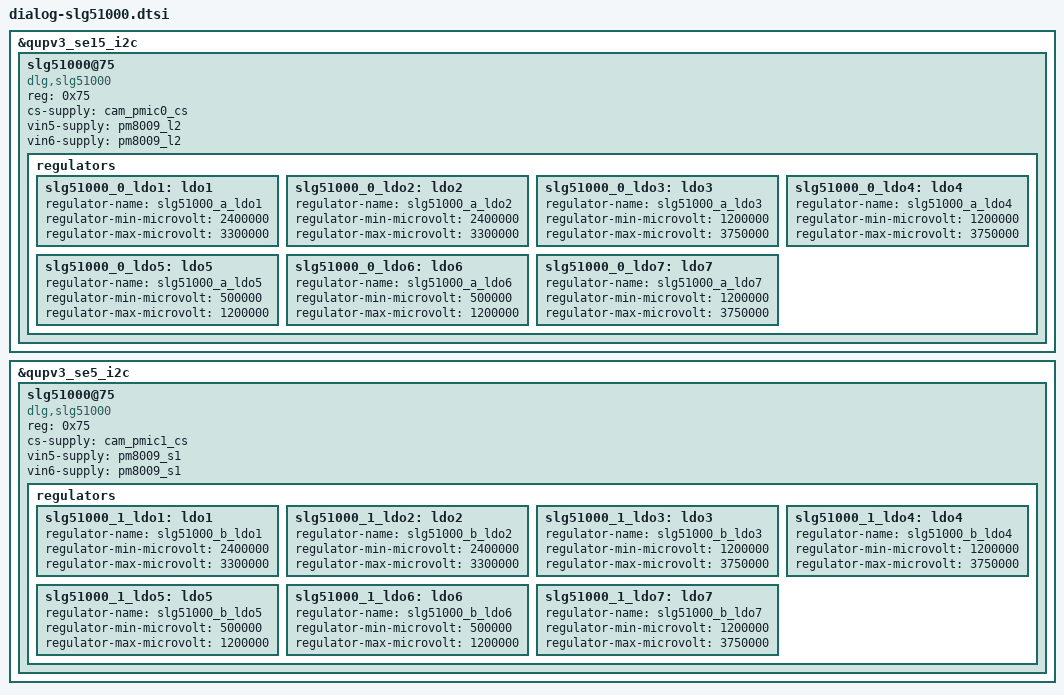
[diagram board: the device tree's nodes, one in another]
/* arch/arm64/boot/dts/somc/dialog-slg51000.dtsi
 *
 * This program is free software; you can redistribute it and/or modify
 * it under the terms of the GNU General Public License version 2 and
 * only version 2 as published by the Free Software Foundation.
 *
 * This program is distributed in the hope that it will be useful,
 * but WITHOUT ANY WARRANTY; without even the implied warranty of
 * MERCHANTABILITY or FITNESS FOR A PARTICULAR PURPOSE.  See the
 * GNU General Public License for more details.
 */

/*
 * use QUP15 I2C for slg51000_0
 */
&qupv3_se15_i2c {
	slg51000@75 {
		compatible = "dlg,slg51000";
		reg = <0x75>;
		cs-supply = <&cam_pmic0_cs>;
		vin5-supply = <&pm8009_l2>;
		vin6-supply = <&pm8009_l2>;

		regulators {
			slg51000_0_ldo1: ldo1 {
				regulator-name = "slg51000_a_ldo1";
				regulator-min-microvolt = <2400000>;
				regulator-max-microvolt = <3300000>;
			};

			slg51000_0_ldo2: ldo2 {
				regulator-name = "slg51000_a_ldo2";
				regulator-min-microvolt = <2400000>;
				regulator-max-microvolt = <3300000>;
			};

			slg51000_0_ldo3: ldo3 {
				regulator-name = "slg51000_a_ldo3";
				regulator-min-microvolt = <1200000>;
				regulator-max-microvolt = <3750000>;
			};

			slg51000_0_ldo4: ldo4 {
				regulator-name = "slg51000_a_ldo4";
				regulator-min-microvolt = <1200000>;
				regulator-max-microvolt = <3750000>;
			};

			slg51000_0_ldo5: ldo5 {
				regulator-name = "slg51000_a_ldo5";
				regulator-min-microvolt = <500000>;
				regulator-max-microvolt = <1200000>;
			};

			slg51000_0_ldo6: ldo6 {
				regulator-name = "slg51000_a_ldo6";
				regulator-min-microvolt = <500000>;
				regulator-max-microvolt = <1200000>;
			};

			slg51000_0_ldo7: ldo7 {
				regulator-name = "slg51000_a_ldo7";
				regulator-min-microvolt = <1200000>;
				regulator-max-microvolt = <3750000>;
			};
		};
	};
};

/*
 * use QUP5 I2C for slg51000_1
 */
&qupv3_se5_i2c {
	slg51000@75 {
		compatible = "dlg,slg51000";
		reg = <0x75>;
		cs-supply = <&cam_pmic1_cs>;
		vin5-supply = <&pm8009_s1>;
		vin6-supply = <&pm8009_s1>;

		regulators {
			slg51000_1_ldo1: ldo1 {
				regulator-name = "slg51000_b_ldo1";
				regulator-min-microvolt = <2400000>;
				regulator-max-microvolt = <3300000>;
			};

			slg51000_1_ldo2: ldo2 {
				regulator-name = "slg51000_b_ldo2";
				regulator-min-microvolt = <2400000>;
				regulator-max-microvolt = <3300000>;
			};

			slg51000_1_ldo3: ldo3 {
				regulator-name = "slg51000_b_ldo3";
				regulator-min-microvolt = <1200000>;
				regulator-max-microvolt = <3750000>;
			};

			slg51000_1_ldo4: ldo4 {
				regulator-name = "slg51000_b_ldo4";
				regulator-min-microvolt = <1200000>;
				regulator-max-microvolt = <3750000>;
			};

			slg51000_1_ldo5: ldo5 {
				regulator-name = "slg51000_b_ldo5";
				regulator-min-microvolt = <500000>;
				regulator-max-microvolt = <1200000>;
			};

			slg51000_1_ldo6: ldo6 {
				regulator-name = "slg51000_b_ldo6";
				regulator-min-microvolt = <500000>;
				regulator-max-microvolt = <1200000>;
			};

			slg51000_1_ldo7: ldo7 {
				regulator-name = "slg51000_b_ldo7";
				regulator-min-microvolt = <1200000>;
				regulator-max-microvolt = <3750000>;
			};
		};
	};
};
